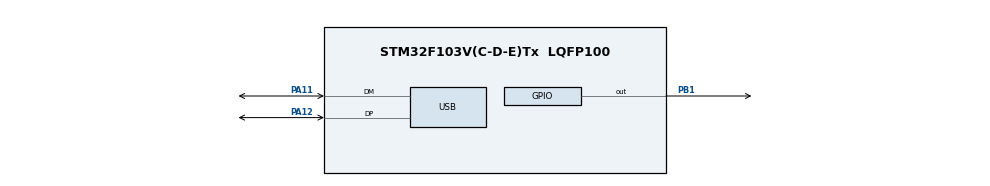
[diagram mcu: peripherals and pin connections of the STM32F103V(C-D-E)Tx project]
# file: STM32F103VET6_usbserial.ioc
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Mcu.Family=STM32F1
Mcu.Name=STM32F103V(C-D-E)Tx
Mcu.Package=LQFP100
NVIC.PriorityGroup=NVIC_PRIORITYGROUP_4
NVIC.USB_LP_CAN1_RX0_IRQn=true\:0\:0\:false\:false\:true\:false\:true
PA11.Mode=Device
PA11.Signal=USB_DM
PA12.Mode=Device
PA12.Signal=USB_DP
PB1.Signal=GPIO_Output
ProjectManager.HeapSize=0x200
ProjectManager.StackSize=0x400
ProjectManager.TargetToolchain=Makefile
RCC.APB1Freq_Value=8000000
RCC.APB2Freq_Value=8000000
RCC.PLLSourceVirtualString=RCC_PLLSOURCE_HSI_DIV2
USB_DEVICE.CLASS_NAME_FS=CDC
USB_DEVICE.VirtualMode=Cdc
USB_DEVICE.VirtualModeFS=Cdc_FS
VP_SYS_VS_ND.Mode=No_Debug
VP_USB_DEVICE_VS_USB_DEVICE_CDC_FS.Mode=CDC_FS
board=custom

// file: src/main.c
/* USER CODE BEGIN Header */
/**
******************************************************************************
* @file           : main.c
* @brief          : Main program body
******************************************************************************
* @attention
*
* <h2><center>&copy; Copyright (c) 2019 STMicroelectronics.
* All rights reserved.</center></h2>
*
* This software component is licensed by ST under Ultimate Liberty license
* SLA0044, the "License"; You may not use this file except in compliance with
* the License. You may obtain a copy of the License at:
*                             www.st.com/SLA0044
*
******************************************************************************
*/
/* USER CODE END Header */

#include "main.h"
#include "usb_device.h"
#include "crc16.h"
#include "stm32f1xx_it.h"
#include "stm32f1xx_hal.h"
#include "packet.h"

void SystemClock_Config(void);
/* USER CODE BEGIN PFP */
typedef void (*pFunction)();
/* USER CODE END PFP */

/* USER CODE BEGIN 0 */
uint8_t USB_rx_buffer[0x7F];
volatile uint8_t USB_rx_buffer_lead_ptr;
volatile uint8_t gSystemInitialized = 0;
/* USER CODE END 0 */

static flasher_state_t flasher_state = NOT_IN;

static void __attribute__ ((noreturn)) flasher_main()
{

    packet_parser_init();

#if ENABLE_BOOTLOADER_PROTECTION
    /* Ensures that the first sector of flash is write-protected preventing that the
       bootloader is overwritten */
    CHECK_AND_SET_FLASH_PROTECTION();
#endif

    flasher_state = WAITING;

    packet_t p = { 0 };

    for(;;) {
        if (USB_rx_buffer_lead_ptr > 0) {
            packet_parser_bulk_push(USB_rx_buffer, USB_rx_buffer_lead_ptr);
            while (packet_parse(&p)) {
                if(p.destination_id == 1) {
                    /* dispatch_packet(&p); */
                }
            }
            USB_rx_buffer_lead_ptr = 0;
            USBD_CDC_ReceivePacket(&hUsbDeviceFS);
        }
    }
}

int main(void)
{

    /* MCU Configuration--------------------------------------------------------*/

    /* Reset of all peripherals, Initializes the Flash interface and the Systick. */
    HAL_Init();

    /* Configure the system clock */
    SystemClock_Config();

    /* Initialize all configured peripherals */
    MX_GPIO_Init();
    MX_USB_DEVICE_Init();
    flasher_main();
    /* Infinite loop */
    while (1)
    {

    }
}

void SystemClock_Config(void)
{
    RCC_OscInitTypeDef RCC_OscInitStruct = {0};
    RCC_ClkInitTypeDef RCC_ClkInitStruct = {0};
    RCC_PeriphCLKInitTypeDef PeriphClkInit = {0};

    /** Initializes the CPU, AHB and APB busses clocks
     */
    RCC_OscInitStruct.OscillatorType = RCC_OSCILLATORTYPE_HSI;
    RCC_OscInitStruct.HSIState = RCC_HSI_ON;
    RCC_OscInitStruct.HSICalibrationValue = RCC_HSICALIBRATION_DEFAULT;
    RCC_OscInitStruct.PLL.PLLState = RCC_PLL_ON;
    RCC_OscInitStruct.PLL.PLLSource = RCC_PLLSOURCE_HSI_DIV2;
    RCC_OscInitStruct.PLL.PLLMUL = RCC_PLL_MUL2;
    if (HAL_RCC_OscConfig(&RCC_OscInitStruct) != HAL_OK)
    {
        Error_Handler();
    }
    /** Initializes the CPU, AHB and APB busses clocks
     */
    RCC_ClkInitStruct.ClockType = RCC_CLOCKTYPE_HCLK|RCC_CLOCKTYPE_SYSCLK
        |RCC_CLOCKTYPE_PCLK1|RCC_CLOCKTYPE_PCLK2;
    RCC_ClkInitStruct.SYSCLKSource = RCC_SYSCLKSOURCE_HSI;
    RCC_ClkInitStruct.AHBCLKDivider = RCC_SYSCLK_DIV1;
    RCC_ClkInitStruct.APB1CLKDivider = RCC_HCLK_DIV1;
    RCC_ClkInitStruct.APB2CLKDivider = RCC_HCLK_DIV1;

    if (HAL_RCC_ClockConfig(&RCC_ClkInitStruct, FLASH_LATENCY_0) != HAL_OK)
    {
        Error_Handler();
    }
    PeriphClkInit.PeriphClockSelection = RCC_PERIPHCLK_USB;
    PeriphClkInit.UsbClockSelection = RCC_USBCLKSOURCE_PLL;
    if (HAL_RCCEx_PeriphCLKConfig(&PeriphClkInit) != HAL_OK)
    {
        Error_Handler();
    }
}

/* USER CODE BEGIN 4 */

void main_tick_1ms() {}
void main_tick_5ms() {
    USB_SendTick();
}
void main_tick_10ms()  {}
void main_tick_50ms()  {
    /* if (toggle_time_r > 0) { */
    /*     HAL_GPIO_TogglePin(GPIOB, LED_R_Pin); */
    /*     toggle_time_r--; */
    /* } */
    /* if (toggle_time_g > 0) { */
    /*     HAL_GPIO_TogglePin(GPIOB, LED_G_Pin); */
    /*     toggle_time_g--; */
    /* } */
    /* if (toggle_time_b > 0) { */
    /*     HAL_GPIO_TogglePin(GPIOB, LED_B_Pin); */
    /*     toggle_time_b--; */
    /* } */
}
void main_tick_100ms() {}
void main_tick_500ms() {}
void main_tick_1s() {}

/* USER CODE END 4 */

void Error_Handler(void)
{
}

/************************ (C) COPYRIGHT STMicroelectronics *****END OF FILE****/
